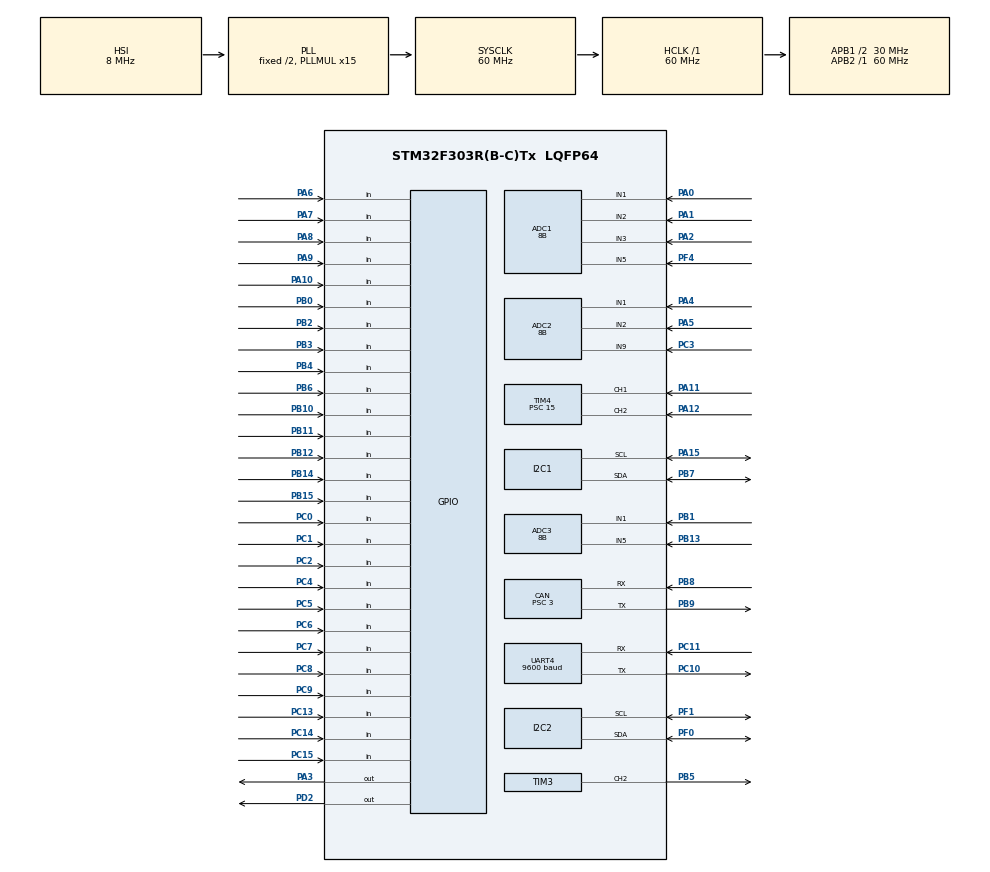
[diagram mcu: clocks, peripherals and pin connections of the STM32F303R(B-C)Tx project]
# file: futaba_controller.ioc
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ADC1.Channel-0\#ChannelRegularConversion=ADC_CHANNEL_1
ADC1.Channel-1\#ChannelRegularConversion=ADC_CHANNEL_3
ADC1.Channel-2\#ChannelRegularConversion=ADC_CHANNEL_2
ADC1.Channel-3\#ChannelRegularConversion=ADC_CHANNEL_5
ADC1.ContinuousConvMode=ENABLE
ADC1.DMAContinuousRequests=ENABLE
ADC1.LowPowerAutoWait=ENABLE
ADC1.NbrOfConversion=4
ADC1.NbrOfConversionFlag=1
ADC1.Offset-0\#ChannelRegularConversion=0
ADC1.Offset-1\#ChannelRegularConversion=0
ADC1.Offset-2\#ChannelRegularConversion=0
ADC1.Offset-3\#ChannelRegularConversion=0
ADC1.OffsetNumber-0\#ChannelRegularConversion=ADC_OFFSET_NONE
ADC1.OffsetNumber-1\#ChannelRegularConversion=ADC_OFFSET_NONE
ADC1.OffsetNumber-2\#ChannelRegularConversion=ADC_OFFSET_NONE
ADC1.OffsetNumber-3\#ChannelRegularConversion=ADC_OFFSET_NONE
ADC1.Rank-0\#ChannelRegularConversion=1
ADC1.Rank-1\#ChannelRegularConversion=2
ADC1.Rank-2\#ChannelRegularConversion=3
ADC1.Rank-3\#ChannelRegularConversion=4
ADC1.Resolution=ADC_RESOLUTION_8B
ADC1.SamplingTime-0\#ChannelRegularConversion=ADC_SAMPLETIME_601CYCLES_5
ADC1.SamplingTime-1\#ChannelRegularConversion=ADC_SAMPLETIME_601CYCLES_5
ADC1.SamplingTime-2\#ChannelRegularConversion=ADC_SAMPLETIME_601CYCLES_5
ADC1.SamplingTime-3\#ChannelRegularConversion=ADC_SAMPLETIME_601CYCLES_5
ADC1.master=1
ADC2.Channel-3\#ChannelRegularConversion=ADC_CHANNEL_9
ADC2.Channel-4\#ChannelRegularConversion=ADC_CHANNEL_2
ADC2.Channel-5\#ChannelRegularConversion=ADC_CHANNEL_1
ADC2.ContinuousConvMode=ENABLE
ADC2.DMAContinuousRequests=ENABLE
ADC2.InjNumberOfConversion=1
ADC2.InjectedChannel-6\#ChannelInjectedConversion=ADC_CHANNEL_1
ADC2.InjectedOffset-6\#ChannelInjectedConversion=0
ADC2.InjectedOffsetNumber-6\#ChannelInjectedConversion=ADC_OFFSET_NONE
ADC2.InjectedRank-6\#ChannelInjectedConversion=1
ADC2.InjectedSamplingTime-6\#ChannelInjectedConversion=ADC_SAMPLETIME_1CYCLE_5
ADC2.InjectedSamplingTimeOPAMP-6\#ChannelInjectedConversion=ADC_SAMPLETIME_61CYCLES_5
ADC2.LowPowerAutoWait=ENABLE
ADC2.NbrOfConversion=3
ADC2.NbrOfConversionFlag=1
ADC2.Offset-3\#ChannelRegularConversion=0
ADC2.Offset-4\#ChannelRegularConversion=0
ADC2.Offset-5\#ChannelRegularConversion=0
ADC2.OffsetNumber-3\#ChannelRegularConversion=ADC_OFFSET_NONE
ADC2.OffsetNumber-4\#ChannelRegularConversion=ADC_OFFSET_NONE
ADC2.OffsetNumber-5\#ChannelRegularConversion=ADC_OFFSET_NONE
ADC2.Rank-3\#ChannelRegularConversion=1
ADC2.Rank-4\#ChannelRegularConversion=2
ADC2.Rank-5\#ChannelRegularConversion=3
ADC2.Resolution=ADC_RESOLUTION_8B
ADC2.SamplingTime-3\#ChannelRegularConversion=ADC_SAMPLETIME_601CYCLES_5
ADC2.SamplingTime-4\#ChannelRegularConversion=ADC_SAMPLETIME_601CYCLES_5
ADC2.SamplingTime-5\#ChannelRegularConversion=ADC_SAMPLETIME_601CYCLES_5
ADC3.Channel-1\#ChannelRegularConversion=ADC_CHANNEL_1
ADC3.Channel-2\#ChannelRegularConversion=ADC_CHANNEL_5
ADC3.ContinuousConvMode=ENABLE
ADC3.DMAContinuousRequests=ENABLE
ADC3.LowPowerAutoWait=ENABLE
ADC3.NbrOfConversion=2
ADC3.NbrOfConversionFlag=1
ADC3.Offset-1\#ChannelRegularConversion=0
ADC3.Offset-2\#ChannelRegularConversion=0
ADC3.OffsetNumber-1\#ChannelRegularConversion=ADC_OFFSET_NONE
ADC3.OffsetNumber-2\#ChannelRegularConversion=ADC_OFFSET_NONE
ADC3.Rank-1\#ChannelRegularConversion=1
ADC3.Rank-2\#ChannelRegularConversion=2
ADC3.Resolution=ADC_RESOLUTION_8B
ADC3.SamplingTime-1\#ChannelRegularConversion=ADC_SAMPLETIME_601CYCLES_5
ADC3.SamplingTime-2\#ChannelRegularConversion=ADC_SAMPLETIME_601CYCLES_5
ADC3.SamplingTimeOPAMP-2\#ChannelRegularConversion=ADC_SAMPLETIME_61CYCLES_5
ADC3.master=1
CAN.ABOM=ENABLE
CAN.BS1=CAN_BS1_7TQ
CAN.BS2=CAN_BS2_2TQ
CAN.CalculateBaudRate=1000000
CAN.CalculateTimeBit=1000
CAN.CalculateTimeQuantum=100.0
CAN.NART=ENABLE
CAN.Prescaler=3
Dma.ADC1.2.Direction=DMA_PERIPH_TO_MEMORY
Dma.ADC1.2.Instance=DMA1_Channel1
Dma.ADC1.2.MemDataAlignment=DMA_MDATAALIGN_BYTE
Dma.ADC1.2.MemInc=DMA_MINC_ENABLE
Dma.ADC1.2.Mode=DMA_CIRCULAR
Dma.ADC1.2.PeriphDataAlignment=DMA_PDATAALIGN_BYTE
Dma.ADC1.2.PeriphInc=DMA_PINC_DISABLE
Dma.ADC1.2.Priority=DMA_PRIORITY_LOW
Dma.ADC2.0.Direction=DMA_PERIPH_TO_MEMORY
Dma.ADC2.0.Instance=DMA2_Channel1
Dma.ADC2.0.MemDataAlignment=DMA_MDATAALIGN_BYTE
Dma.ADC2.0.MemInc=DMA_MINC_ENABLE
Dma.ADC2.0.Mode=DMA_CIRCULAR
Dma.ADC2.0.PeriphDataAlignment=DMA_PDATAALIGN_BYTE
Dma.ADC2.0.PeriphInc=DMA_PINC_DISABLE
Dma.ADC2.0.Priority=DMA_PRIORITY_LOW
Dma.ADC3.1.Direction=DMA_PERIPH_TO_MEMORY
Dma.ADC3.1.Instance=DMA2_Channel5
Dma.ADC3.1.MemDataAlignment=DMA_MDATAALIGN_BYTE
Dma.ADC3.1.MemInc=DMA_MINC_ENABLE
Dma.ADC3.1.Mode=DMA_CIRCULAR
Dma.ADC3.1.PeriphDataAlignment=DMA_PDATAALIGN_BYTE
Dma.ADC3.1.PeriphInc=DMA_PINC_DISABLE
Dma.ADC3.1.Priority=DMA_PRIORITY_LOW
Dma.Request0=ADC2
Dma.Request1=ADC3
Dma.Request2=ADC1
Mcu.Family=STM32F3
Mcu.Name=STM32F303R(B-C)Tx
Mcu.Package=LQFP64
NVIC.DMA1_Channel1_IRQn=true\:0\:0\:false\:false\:true\:false\:true\:true
NVIC.DMA2_Channel1_IRQn=true\:0\:0\:false\:false\:true\:false\:true\:true
NVIC.DMA2_Channel5_IRQn=true\:0\:0\:false\:false\:true\:false\:true\:true
NVIC.PriorityGroup=NVIC_PRIORITYGROUP_4
NVIC.TIM1_TRG_COM_TIM17_IRQn=true\:0\:0\:false\:false\:true\:true\:true\:true
NVIC.TIM1_UP_TIM16_IRQn=true\:0\:0\:false\:false\:true\:true\:true\:true
NVIC.UART4_IRQn=true\:0\:0\:false\:false\:true\:true\:true\:true
NVIC.USB_HP_CAN_TX_IRQn=true\:0\:0\:false\:false\:true\:true\:true\:true
NVIC.USB_LP_CAN_RX0_IRQn=true\:0\:0\:false\:false\:true\:true\:true\:true
PA0.Mode=IN1-Single-Ended
PA0.Signal=ADC1_IN1
PA1.Mode=IN2-Single-Ended
PA1.Signal=ADC1_IN2
PA10.GPIO_PuPd=GPIO_PULLUP
PA10.Signal=GPIO_Input
PA11.GPIO_PuPd=GPIO_PULLUP
PA11.Signal=S_TIM4_CH1
PA12.GPIO_PuPd=GPIO_PULLUP
PA12.Signal=S_TIM4_CH2
PA13.Signal=SYS_JTMS-SWDIO
PA14.Signal=SYS_JTCK-SWCLK
PA15.GPIO_Pu=GPIO_PULLUP
PA15.Mode=I2C
PA15.Signal=I2C1_SCL
PA2.Mode=IN3-Single-Ended
PA2.Signal=ADC1_IN3
PA3.Signal=GPIO_Output
PA4.Mode=IN1-Single-Ended
PA4.Signal=ADC2_IN1
PA5.Mode=IN2-Single-Ended
PA5.Signal=ADC2_IN2
PA6.Signal=GPIO_Input
PA7.Signal=GPIO_Input
PA8.GPIO_PuPd=GPIO_PULLUP
PA8.Signal=GPIO_Input
PA9.GPIO_PuPd=GPIO_PULLUP
PA9.Signal=GPIO_Input
PB0.Signal=GPIO_Input
PB1.Mode=IN1-Single-Ended
PB1.Signal=ADC3_IN1
PB10.GPIO_PuPd=GPIO_PULLUP
PB10.Signal=GPIO_Input
PB11.Signal=GPIO_Input
PB12.Signal=GPIO_Input
PB13.Mode=IN5-Single-Ended
PB13.Signal=ADC3_IN5
PB14.Signal=GPIO_Input
PB15.GPIO_PuPd=GPIO_PULLUP
PB15.Signal=GPIO_Input
PB2.GPIO_PuPd=GPIO_PULLUP
PB2.Signal=GPIO_Input
PB3.GPIO_PuPd=GPIO_PULLUP
PB3.Signal=GPIO_Input
PB4.GPIO_PuPd=GPIO_PULLUP
PB4.Signal=GPIO_Input
PB5.Signal=S_TIM3_CH2
PB6.GPIO_PuPd=GPIO_PULLUP
PB6.Signal=GPIO_Input
PB7.GPIO_Pu=GPIO_PULLUP
PB7.Mode=I2C
PB7.Signal=I2C1_SDA
PB8.Mode=CAN_Activate
PB8.Signal=CAN_RX
PB9.Mode=CAN_Activate
PB9.Signal=CAN_TX
PC0.GPIO_PuPd=GPIO_PULLUP
PC0.Signal=GPIO_Input
PC1.GPIO_PuPd=GPIO_PULLUP
PC1.Signal=GPIO_Input
PC10.Mode=Asynchronous
PC10.Signal=UART4_TX
PC11.Mode=Asynchronous
PC11.Signal=UART4_RX
PC13.GPIO_PuPd=GPIO_PULLUP
PC13.Signal=GPIO_Input
PC14-OSC32_IN.GPIO_PuPd=GPIO_PULLUP
PC14-OSC32_IN.Signal=GPIO_Input
PC15-OSC32_OUT.GPIO_PuPd=GPIO_PULLUP
PC15-OSC32_OUT.Signal=GPIO_Input
PC2.GPIO_PuPd=GPIO_PULLUP
PC2.Signal=GPIO_Input
PC3.Signal=ADCx_IN9
PC4.GPIO_PuPd=GPIO_PULLUP
PC4.Signal=GPIO_Input
PC5.GPIO_PuPd=GPIO_PULLUP
PC5.Signal=GPIO_Input
PC6.GPIO_PuPd=GPIO_PULLUP
PC6.Signal=GPIO_Input
PC7.GPIO_PuPd=GPIO_PULLUP
PC7.Signal=GPIO_Input
PC8.GPIO_PuPd=GPIO_PULLUP
PC8.Signal=GPIO_Input
PC9.GPIO_PuPd=GPIO_PULLUP
PC9.Signal=GPIO_Input
PD2.Signal=GPIO_Output
PF0-OSC_IN.GPIO_Pu=GPIO_PULLUP
PF0-OSC_IN.Mode=I2C
PF0-OSC_IN.Signal=I2C2_SDA
PF1-OSC_OUT.GPIO_Pu=GPIO_PULLUP
PF1-OSC_OUT.Mode=I2C
PF1-OSC_OUT.Signal=I2C2_SCL
PF4.Mode=IN5-Single-Ended
PF4.Signal=ADC1_IN5
ProjectManager.HeapSize=0x200
ProjectManager.StackSize=0x400
ProjectManager.TargetToolchain=STM32CubeIDE
RCC.AHBFreq_Value=60000000
RCC.APB1CLKDivider=RCC_HCLK_DIV2
RCC.APB1Freq_Value=30000000
RCC.APB1TimFreq_Value=60000000
RCC.APB2Freq_Value=60000000
RCC.APB2TimFreq_Value=60000000
RCC.CortexFreq_Value=60000000
RCC.HCLKFreq_Value=60000000
RCC.HSE_VALUE=8000000
RCC.HSI_VALUE=8000000
RCC.LSE_VALUE=32768
RCC.PLLMUL=RCC_PLL_MUL15
RCC.SYSCLKFreq_VALUE=60000000
RCC.SYSCLKSourceVirtual=RCC_SYSCLKSOURCE_PLLCLK
RCC.USBFreq_Value=60000000
SH.ADCx_IN9.0=ADC2_IN9,IN9-Single-Ended
SH.S_TIM3_CH2.0=TIM3_CH2,PWM Generation2 CH2
SH.S_TIM4_CH1.0=TIM4_CH1,Encoder_Interface
SH.S_TIM4_CH2.0=TIM4_CH2,Encoder_Interface
TIM16.Period=999
TIM16.Prescaler=5999
TIM17.Period=3999
TIM17.Prescaler=15
TIM3.Channel-PWM\ Generation2\ CH2=TIM_CHANNEL_2
TIM3.Period=3999
TIM3.Prescaler=14
TIM4.Period=3999
TIM4.Prescaler=15
UART4.BaudRate=9600
UART4.Parity=PARITY_EVEN
UART4.WordLength=WORDLENGTH_9B
VP_TIM16_VS_ClockSourceINT.Mode=Enable_Timer
VP_TIM17_VS_ClockSourceINT.Mode=Enable_Timer
board=custom

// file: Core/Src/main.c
/* USER CODE BEGIN Header */
/**
  ******************************************************************************
  * @file           : main.c
  * @brief          : Main program body
  ******************************************************************************
  * @attention
  *
  * <h2><center>&copy; Copyright (c) 2020 STMicroelectronics.
  * All rights reserved.</center></h2>
  *
  * This software component is licensed by ST under BSD 3-Clause license,
  * the "License"; You may not use this file except in compliance with the
  * License. You may obtain a copy of the License at:
  *                        opensource.org/licenses/BSD-3-Clause
  *
  ******************************************************************************
  */
/* USER CODE END Header */
#include "main.h"
#include "adc.h"
#include "can.h"
#include "dma.h"
#include "i2c.h"
#include "tim.h"
#include "usart.h"
#include "gpio.h"

/* USER CODE BEGIN Includes */
#include "wrapper.hpp"//written by user
/* USER CODE END Includes */

void SystemClock_Config(void);

int main(void)
{

  /* MCU Configuration--------------------------------------------------------*/

  /* Reset of all peripherals, Initializes the Flash interface and the Systick. */
  HAL_Init();

  /* Configure the system clock */
  SystemClock_Config();

  /* Initialize all configured peripherals */
  MX_GPIO_Init();
  MX_DMA_Init();
  MX_ADC1_Init();
  MX_ADC2_Init();
  MX_ADC3_Init();
  MX_I2C1_Init();
  MX_I2C2_Init();
  MX_UART4_Init();
  MX_TIM3_Init();
  MX_TIM4_Init();
  MX_TIM17_Init();
  MX_TIM16_Init();
  MX_CAN_Init();
  /* USER CODE BEGIN 2 */
  init();//written by user
  /* USER CODE END 2 */

  /* Infinite loop */
  while (1)
  {

    /* USER CODE BEGIN 3 */
	  loop();//written by user
  }
  /* USER CODE END 3 */
}

void SystemClock_Config(void)
{
  RCC_OscInitTypeDef RCC_OscInitStruct = {0};
  RCC_ClkInitTypeDef RCC_ClkInitStruct = {0};
  RCC_PeriphCLKInitTypeDef PeriphClkInit = {0};

  /** Initializes the RCC Oscillators according to the specified parameters
  * in the RCC_OscInitTypeDef structure.
  */
  RCC_OscInitStruct.OscillatorType = RCC_OSCILLATORTYPE_HSI;
  RCC_OscInitStruct.HSIState = RCC_HSI_ON;
  RCC_OscInitStruct.HSICalibrationValue = RCC_HSICALIBRATION_DEFAULT;
  RCC_OscInitStruct.PLL.PLLState = RCC_PLL_ON;
  RCC_OscInitStruct.PLL.PLLSource = RCC_PLLSOURCE_HSI;
  RCC_OscInitStruct.PLL.PLLMUL = RCC_PLL_MUL15;
  if (HAL_RCC_OscConfig(&RCC_OscInitStruct) != HAL_OK)
  {
    Error_Handler();
  }
  /** Initializes the CPU, AHB and APB buses clocks
  */
  RCC_ClkInitStruct.ClockType = RCC_CLOCKTYPE_HCLK|RCC_CLOCKTYPE_SYSCLK
                              |RCC_CLOCKTYPE_PCLK1|RCC_CLOCKTYPE_PCLK2;
  RCC_ClkInitStruct.SYSCLKSource = RCC_SYSCLKSOURCE_PLLCLK;
  RCC_ClkInitStruct.AHBCLKDivider = RCC_SYSCLK_DIV1;
  RCC_ClkInitStruct.APB1CLKDivider = RCC_HCLK_DIV2;
  RCC_ClkInitStruct.APB2CLKDivider = RCC_HCLK_DIV1;

  if (HAL_RCC_ClockConfig(&RCC_ClkInitStruct, FLASH_LATENCY_2) != HAL_OK)
  {
    Error_Handler();
  }
  PeriphClkInit.PeriphClockSelection = RCC_PERIPHCLK_UART4|RCC_PERIPHCLK_I2C1
                              |RCC_PERIPHCLK_I2C2|RCC_PERIPHCLK_ADC12
                              |RCC_PERIPHCLK_ADC34;
  PeriphClkInit.Uart4ClockSelection = RCC_UART4CLKSOURCE_PCLK1;
  PeriphClkInit.Adc12ClockSelection = RCC_ADC12PLLCLK_DIV1;
  PeriphClkInit.Adc34ClockSelection = RCC_ADC34PLLCLK_DIV1;
  PeriphClkInit.I2c1ClockSelection = RCC_I2C1CLKSOURCE_HSI;
  PeriphClkInit.I2c2ClockSelection = RCC_I2C2CLKSOURCE_HSI;
  if (HAL_RCCEx_PeriphCLKConfig(&PeriphClkInit) != HAL_OK)
  {
    Error_Handler();
  }
}

void Error_Handler(void)
{
}

/************************ (C) COPYRIGHT STMicroelectronics *****END OF FILE****/
